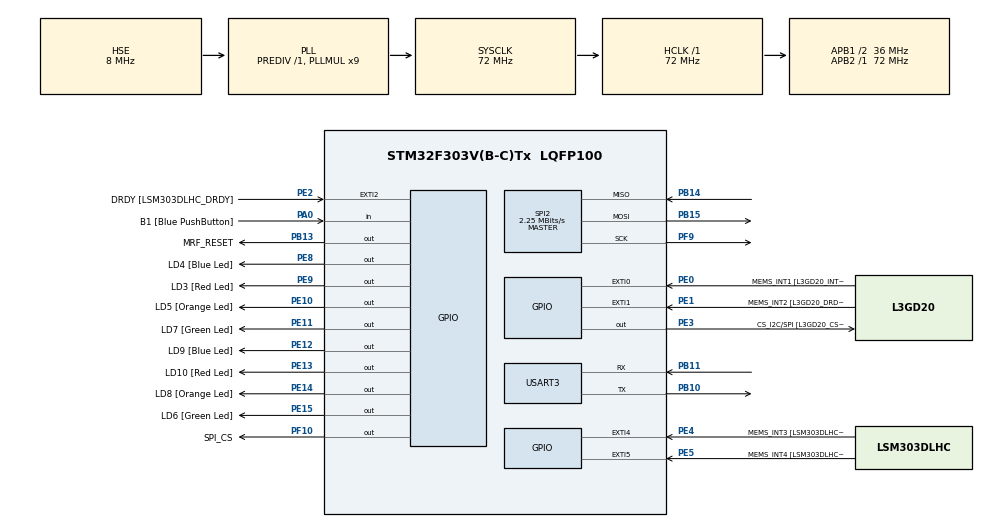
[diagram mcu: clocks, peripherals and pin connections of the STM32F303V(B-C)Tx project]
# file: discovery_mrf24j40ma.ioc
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Mcu.Family=STM32F3
Mcu.Name=STM32F303V(B-C)Tx
Mcu.Package=LQFP100
NVIC.PriorityGroup=NVIC_PRIORITYGROUP_0
NVIC.USART3_IRQn=true\:0\:0\:false\:false\:true
PA0.GPIO_Label=B1 [Blue PushButton]
PA0.GPIO_Mode=GPIO_MODE_INPUT
PA0.GPIO_PuPd=GPIO_NOPULL
PA0.Signal=GPIO_Input
PA11.GPIO_Label=DM
PA11.Signal=USB_DM
PA12.GPIO_Label=DP
PA12.Signal=USB_DP
PA13.GPIO_Label=SWDIO
PA13.Signal=SYS_JTMS-SWDIO
PA14.GPIO_Label=SWCLK
PA14.Signal=SYS_JTCK-SWCLK
PA5.GPIO_Label=SPI1_SCK [L3GD20_SCL/SPC]
PA5.GPIO_Mode=GPIO_MODE_AF_PP
PA5.GPIO_PuPd=GPIO_NOPULL
PA5.GPIO_Speed=GPIO_SPEED_FREQ_LOW
PA5.Signal=SPI1_SCK
PA6.GPIO_Label=SPI1_MISO [L3GD20_SA0/SDO]
PA6.GPIO_Mode=GPIO_MODE_AF_PP
PA6.GPIO_PuPd=GPIO_NOPULL
PA6.GPIO_Speed=GPIO_SPEED_FREQ_LOW
PA6.Signal=SPI1_MISO
PA7.GPIO_Label=SPI1_MISO [L3GD20_SDA/SDI/SDO]
PA7.GPIO_Mode=GPIO_MODE_AF_PP
PA7.GPIO_PuPd=GPIO_NOPULL
PA7.GPIO_Speed=GPIO_SPEED_FREQ_LOW
PA7.Signal=SPI1_MOSI
PB10.GPIO_PuPd=GPIO_PULLUP
PB10.Mode=Asynchronous
PB10.Signal=USART3_TX
PB11.GPIO_PuPd=GPIO_PULLUP
PB11.Mode=Asynchronous
PB11.Signal=USART3_RX
PB13.GPIO_Label=MRF_RESET
PB13.GPIO_Speed=GPIO_SPEED_FREQ_HIGH
PB13.Signal=GPIO_Output
PB14.GPIO_PuPd=GPIO_PULLUP
PB14.Mode=Full_Duplex_Master
PB14.Signal=SPI2_MISO
PB15.GPIO_PuPd=GPIO_PULLUP
PB15.Mode=Full_Duplex_Master
PB15.Signal=SPI2_MOSI
PB3.GPIO_Label=SWO
PB3.Signal=SYS_JTDO-TRACESWO
PB6.GPIO_FM6=__NULL
PB6.GPIO_Label=I2C1_SCL [LSM303DLHC_SCL]
PB6.GPIO_Mode=GPIO_MODE_AF_OD
PB6.GPIO_PuPd=GPIO_NOPULL
PB6.GPIO_Speed=GPIO_SPEED_FREQ_LOW
PB6.Signal=I2C1_SCL
PB7.GPIO_FM7=__NULL
PB7.GPIO_Label=I2C1_SDA [LSM303DLHC_SDA]
PB7.GPIO_Mode=GPIO_MODE_AF_OD
PB7.GPIO_PuPd=GPIO_NOPULL
PB7.GPIO_Speed=GPIO_SPEED_FREQ_LOW
PB7.Signal=I2C1_SDA
PC14-OSC32_IN.GPIO_Label=OSC32_IN
PC14-OSC32_IN.Signal=RCC_OSC32_IN
PC15-OSC32_OUT.GPIO_Label=OSC32_OUT
PC15-OSC32_OUT.Signal=RCC_OSC32_OUT
PE0.GPIO_Label=MEMS_INT1 [L3GD20_INT1]
PE0.GPIO_ModeDefaultEXTI=GPIO_MODE_EVT_RISING
PE0.GPIO_PuPd=GPIO_NOPULL
PE0.Signal=GPXTI0
PE1.GPIO_Label=MEMS_INT2 [L3GD20_DRDY/INT2]
PE1.GPIO_ModeDefaultEXTI=GPIO_MODE_EVT_RISING
PE1.GPIO_PuPd=GPIO_NOPULL
PE1.Signal=GPXTI1
PE10.GPIO_Label=LD5 [Orange Led]
PE10.GPIO_ModeDefaultOutputPP=GPIO_MODE_OUTPUT_PP
PE10.GPIO_PuPd=GPIO_NOPULL
PE10.GPIO_Speed=GPIO_SPEED_FREQ_LOW
PE10.Signal=GPIO_Output
PE11.GPIO_Label=LD7 [Green Led]
PE11.GPIO_ModeDefaultOutputPP=GPIO_MODE_OUTPUT_PP
PE11.GPIO_PuPd=GPIO_NOPULL
PE11.GPIO_Speed=GPIO_SPEED_FREQ_LOW
PE11.Signal=GPIO_Output
PE12.GPIO_Label=LD9 [Blue Led]
PE12.GPIO_ModeDefaultOutputPP=GPIO_MODE_OUTPUT_PP
PE12.GPIO_PuPd=GPIO_NOPULL
PE12.GPIO_Speed=GPIO_SPEED_FREQ_LOW
PE12.Signal=GPIO_Output
PE13.GPIO_Label=LD10 [Red Led]
PE13.GPIO_ModeDefaultOutputPP=GPIO_MODE_OUTPUT_PP
PE13.GPIO_PuPd=GPIO_NOPULL
PE13.GPIO_Speed=GPIO_SPEED_FREQ_LOW
PE13.Signal=GPIO_Output
PE14.GPIO_Label=LD8 [Orange Led]
PE14.GPIO_ModeDefaultOutputPP=GPIO_MODE_OUTPUT_PP
PE14.GPIO_PuPd=GPIO_NOPULL
PE14.GPIO_Speed=GPIO_SPEED_FREQ_LOW
PE14.Signal=GPIO_Output
PE15.GPIO_Label=LD6 [Green Led]
PE15.GPIO_ModeDefaultOutputPP=GPIO_MODE_OUTPUT_PP
PE15.GPIO_PuPd=GPIO_NOPULL
PE15.GPIO_Speed=GPIO_SPEED_FREQ_LOW
PE15.Signal=GPIO_Output
PE2.GPIO_Label=DRDY [LSM303DLHC_DRDY]
PE2.GPIO_ModeDefaultEXTI=GPIO_MODE_EVT_RISING
PE2.GPIO_PuPd=GPIO_NOPULL
PE2.Signal=GPXTI2
PE3.GPIO_Label=CS_I2C/SPI [L3GD20_CS_I2C/SPI]
PE3.GPIO_ModeDefaultOutputPP=GPIO_MODE_OUTPUT_PP
PE3.GPIO_PuPd=GPIO_NOPULL
PE3.GPIO_Speed=GPIO_SPEED_FREQ_LOW
PE3.Signal=GPIO_Output
PE4.GPIO_Label=MEMS_INT3 [LSM303DLHC_INT1]
PE4.GPIO_ModeDefaultEXTI=GPIO_MODE_EVT_RISING
PE4.GPIO_PuPd=GPIO_NOPULL
PE4.Signal=GPXTI4
PE5.GPIO_Label=MEMS_INT4 [LSM303DLHC_INT2]
PE5.GPIO_ModeDefaultEXTI=GPIO_MODE_EVT_RISING
PE5.GPIO_PuPd=GPIO_NOPULL
PE5.Signal=GPXTI5
PE8.GPIO_Label=LD4 [Blue Led]
PE8.GPIO_ModeDefaultOutputPP=GPIO_MODE_OUTPUT_PP
PE8.GPIO_PuPd=GPIO_NOPULL
PE8.GPIO_Speed=GPIO_SPEED_FREQ_LOW
PE8.Signal=GPIO_Output
PE9.GPIO_Label=LD3 [Red Led]
PE9.GPIO_ModeDefaultOutputPP=GPIO_MODE_OUTPUT_PP
PE9.GPIO_PuPd=GPIO_NOPULL
PE9.GPIO_Speed=GPIO_SPEED_FREQ_LOW
PE9.Signal=GPIO_Output
PF0-OSC_IN.GPIO_Label=OSC_IN
PF0-OSC_IN.Mode=HSE-External-Oscillator
PF0-OSC_IN.Signal=RCC_OSC_IN
PF1-OSC_OUT.GPIO_Label=OSC_OUT
PF1-OSC_OUT.Mode=HSE-External-Oscillator
PF1-OSC_OUT.Signal=RCC_OSC_OUT
PF10.GPIO_Label=SPI_CS
PF10.GPIO_PuPd=GPIO_PULLDOWN
PF10.GPIO_Speed=GPIO_SPEED_FREQ_HIGH
PF10.Signal=GPIO_Output
PF9.GPIO_PuPd=GPIO_PULLUP
PF9.Mode=Full_Duplex_Master
PF9.Signal=SPI2_SCK
ProjectManager.HeapSize=0x200
ProjectManager.StackSize=0x200
ProjectManager.TargetToolchain=SW4STM32
RCC.AHBFreq_Value=72000000
RCC.APB1CLKDivider=RCC_HCLK_DIV2
RCC.APB1Freq_Value=36000000
RCC.APB1TimFreq_Value=72000000
RCC.APB2Freq_Value=72000000
RCC.APB2TimFreq_Value=72000000
RCC.CortexFreq_Value=72000000
RCC.HCLKFreq_Value=72000000
RCC.HSE_VALUE=8000000
RCC.HSI_VALUE=8000000
RCC.LSE_VALUE=32768
RCC.PLLMUL=RCC_PLL_MUL9
RCC.PLLSourceVirtual=RCC_PLLSOURCE_HSE
RCC.SYSCLKFreq_VALUE=72000000
RCC.SYSCLKSourceVirtual=RCC_SYSCLKSOURCE_PLLCLK
RCC.USBFreq_Value=72000000
SPI2.BaudRatePrescaler=SPI_BAUDRATEPRESCALER_16
SPI2.CLKPolarity=SPI_POLARITY_LOW
SPI2.CalculateBaudRate=2.25 MBits/s
SPI2.DataSize=SPI_DATASIZE_8BIT
SPI2.Direction=SPI_DIRECTION_2LINES
SPI2.FirstBit=SPI_FIRSTBIT_MSB
SPI2.Mode=SPI_MODE_MASTER
SPI2.NSSPMode=SPI_NSS_PULSE_ENABLE
SPI2.VirtualType=VM_MASTER
USART3.VirtualMode-Asynchronous=VM_ASYNC
board=STM32F3DISCOVERY

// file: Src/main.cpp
/**
  ******************************************************************************
  * File Name          : main.c
  * Description        : Main program body
  ******************************************************************************
  ** This notice applies to any and all portions of this file
  * that are not between comment pairs USER CODE BEGIN and
  * USER CODE END. Other portions of this file, whether
  * inserted by the user or by software development tools
  * are owned by their respective copyright owners.
  *
  * COPYRIGHT(c) 2017 STMicroelectronics
  *
  * Redistribution and use in source and binary forms, with or without modification,
  * are permitted provided that the following conditions are met:
  *   1. Redistributions of source code must retain the above copyright notice,
  *      this list of conditions and the following disclaimer.
  *   2. Redistributions in binary form must reproduce the above copyright notice,
  *      this list of conditions and the following disclaimer in the documentation
  *      and/or other materials provided with the distribution.
  *   3. Neither the name of STMicroelectronics nor the names of its contributors
  *      may be used to endorse or promote products derived from this software
  *      without specific prior written permission.
  *
  * THIS SOFTWARE IS PROVIDED BY THE COPYRIGHT HOLDERS AND CONTRIBUTORS "AS IS"
  * AND ANY EXPRESS OR IMPLIED WARRANTIES, INCLUDING, BUT NOT LIMITED TO, THE
  * IMPLIED WARRANTIES OF MERCHANTABILITY AND FITNESS FOR A PARTICULAR PURPOSE ARE
  * DISCLAIMED. IN NO EVENT SHALL THE COPYRIGHT HOLDER OR CONTRIBUTORS BE LIABLE
  * FOR ANY DIRECT, INDIRECT, INCIDENTAL, SPECIAL, EXEMPLARY, OR CONSEQUENTIAL
  * DAMAGES (INCLUDING, BUT NOT LIMITED TO, PROCUREMENT OF SUBSTITUTE GOODS OR
  * SERVICES; LOSS OF USE, DATA, OR PROFITS; OR BUSINESS INTERRUPTION) HOWEVER
  * CAUSED AND ON ANY THEORY OF LIABILITY, WHETHER IN CONTRACT, STRICT LIABILITY,
  * OR TORT (INCLUDING NEGLIGENCE OR OTHERWISE) ARISING IN ANY WAY OUT OF THE USE
  * OF THIS SOFTWARE, EVEN IF ADVISED OF THE POSSIBILITY OF SUCH DAMAGE.
  *
  ******************************************************************************
  */
#include "main.h"
#include "stm32f3xx_hal.h"
#include "Mrf24j.h"
#include <stdlib.h>

SPI_HandleTypeDef hspi2;

UART_HandleTypeDef huart3;

/* USER CODE BEGIN PV */
/* Private variables ---------------------------------------------------------*/

/* USER CODE END PV */

void SystemClock_Config(void);
static void MX_GPIO_Init(void);
static void MX_SPI2_Init(void);
static void MX_USART3_UART_Init(void);

/* USER CODE BEGIN PFP */
/* Private function prototypes -----------------------------------------------*/

/* USER CODE END PFP */

void rx_handl();
void tx_handl();
uint8_t recvBuf[1];
constexpr uint16_t RECV_SIZE = 1;
Mrf24j *mrf24j;

int main(void)
{

  /* MCU Configuration----------------------------------------------------------*/

  /* Reset of all peripherals, Initializes the Flash interface and the Systick. */
  HAL_Init();

  /* Configure the system clock */
  SystemClock_Config();

  /* Initialize all configured peripherals */
  MX_GPIO_Init();
  MX_SPI2_Init();
  MX_USART3_UART_Init();

  gpio_pin pin_reset, pin_chip_select, pin_interrupt;

  pin_chip_select.port = SPI_CS_GPIO_Port;
  pin_chip_select.pin = SPI_CS_Pin;

  pin_reset.port = MRF_RESET_GPIO_Port;
  pin_reset.pin = MRF_RESET_Pin;

  mrf24j = new Mrf24j(&hspi2, &pin_reset, &pin_chip_select, &pin_interrupt);
  //Mrf24j mrf24j(&hspi2, &pin_reset, &pin_chip_select, &pin_interrupt);

  HAL_Delay(20);

  mrf24j->reset();
  mrf24j->init();

  mrf24j->set_pan(0x0023);
  // This is _our_ address
  mrf24j->address16_write(0x6001);

  //(word dest16, char * data, byte len) {
  /* Infinite loop */
  /* USER CODE BEGIN WHILE */

  HAL_UART_Receive_IT(&huart3, recvBuf, RECV_SIZE);

  uint8_t data[] = "WELCOME\n\r";
  uint8_t size = sizeof(data) / sizeof(data[0]);
  HAL_UART_Transmit_IT(&huart3, data, size);

  //char one[] = "ABCDEFGIH";
  char one[] = {
      0xf4, 0x3e, 0x01, 0xff, 0xff,
      0x2e, 0x21, 0x00, 0x0b, 0x00, 0x0b, 0x00, 0x10, 0x5e, 0xc0, 0x00, 0x5d, 0x00, 0x5d,
      0x80, 0x39, 0x47, 0x02, 0x33, 0xff, 0xff};
  int da_size = sizeof(one) / sizeof(one[0]);
  mrf24j->send16(0xffff, one, da_size);

  while (1)
  {

    //mrf24j->interrupt_handler();
    //HAL_Delay(100);
    //mrf24j->check_flags(rx_handl, tx_handl);
    mrf24j->send16(0xffff, one, da_size);

    //HAL_Delay(10);
    //mrf24j->read_long(MRF_RFCON0);
    //mrf24j->interrupt_handler();
    //mrf24j->check_flags(rx_handl, tx_handl);

    HAL_Delay(10000);
    /* USER CODE END WHILE */

  }

}
void rx_handl(){

}
void tx_handl(){

}

void HAL_UART_RxCpltCallback(UART_HandleTypeDef *huart){
  // Reactivate uart recv.

  switch(recvBuf[0])
  {
  case 13:
  {
    uint8_t data[] = "\n\r";
    HAL_UART_Transmit(huart, data, 2, 10);
  }
  break;
  case '1':
  {
    uint8_t ret[1];
    ret[0] = mrf24j->get_channel();
    ret[0] += 48 ; // Get ascii representation of decimal numbers.

    uint8_t mess1[] = "CHANNEL: 1";
    uint8_t size1 = sizeof(mess1) / sizeof(mess1[0]);
    HAL_UART_Transmit(huart, mess1, size1,10);
    HAL_UART_Transmit(huart, ret, 1,10);
    uint8_t mess2[] = "\n\r";
    HAL_UART_Transmit(huart, mess2, 2,10);
  }
    break;
  case '2':
  {
    uint16_t ret[2];
    ret[0] = mrf24j->get_pan();
    ret[1] = mrf24j->read_long(MRF_RFCON3);
    ret[0] += 48 ; // Get ascii representation of decimal numbers.

    uint8_t mess1[] = "CHANNEL: 1";
    uint8_t size1 = sizeof(mess1) / sizeof(mess1[0]);
    HAL_UART_Transmit(huart, mess1, size1,10);
    //HAL_UART_Transmit(huart, ret, 1,10);
    uint8_t mess2[] = "\n\r";
    HAL_UART_Transmit(huart, mess2, 2,10);
  }
  break;
  case '3':
  {
    mrf24j->set_pan(0x0077);
  }
  break;
  default:
    HAL_UART_Transmit(huart, recvBuf, RECV_SIZE,10);

  }

  HAL_UART_Receive_IT(huart, recvBuf, RECV_SIZE);
}

/** System Clock Configuration
*/
void SystemClock_Config(void)
{

  RCC_OscInitTypeDef RCC_OscInitStruct;
  RCC_ClkInitTypeDef RCC_ClkInitStruct;
  RCC_PeriphCLKInitTypeDef PeriphClkInit;

    /**Initializes the CPU, AHB and APB busses clocks
    */
  RCC_OscInitStruct.OscillatorType = RCC_OSCILLATORTYPE_HSE;
  RCC_OscInitStruct.HSEState = RCC_HSE_ON;
  RCC_OscInitStruct.HSEPredivValue = RCC_HSE_PREDIV_DIV1;
  RCC_OscInitStruct.HSIState = RCC_HSI_ON;
  RCC_OscInitStruct.PLL.PLLState = RCC_PLL_ON;
  RCC_OscInitStruct.PLL.PLLSource = RCC_PLLSOURCE_HSE;
  RCC_OscInitStruct.PLL.PLLMUL = RCC_PLL_MUL9;
  if (HAL_RCC_OscConfig(&RCC_OscInitStruct) != HAL_OK)
  {
    _Error_Handler(__FILE__, __LINE__);
  }

    /**Initializes the CPU, AHB and APB busses clocks
    */
  RCC_ClkInitStruct.ClockType = RCC_CLOCKTYPE_HCLK|RCC_CLOCKTYPE_SYSCLK
                              |RCC_CLOCKTYPE_PCLK1|RCC_CLOCKTYPE_PCLK2;
  RCC_ClkInitStruct.SYSCLKSource = RCC_SYSCLKSOURCE_PLLCLK;
  RCC_ClkInitStruct.AHBCLKDivider = RCC_SYSCLK_DIV1;
  RCC_ClkInitStruct.APB1CLKDivider = RCC_HCLK_DIV2;
  RCC_ClkInitStruct.APB2CLKDivider = RCC_HCLK_DIV1;

  if (HAL_RCC_ClockConfig(&RCC_ClkInitStruct, FLASH_LATENCY_2) != HAL_OK)
  {
    _Error_Handler(__FILE__, __LINE__);
  }

  PeriphClkInit.PeriphClockSelection = RCC_PERIPHCLK_USART3;
  PeriphClkInit.Usart3ClockSelection = RCC_USART3CLKSOURCE_PCLK1;
  if (HAL_RCCEx_PeriphCLKConfig(&PeriphClkInit) != HAL_OK)
  {
    _Error_Handler(__FILE__, __LINE__);
  }

    /**Configure the Systick interrupt time
    */
  HAL_SYSTICK_Config(HAL_RCC_GetHCLKFreq()/1000);

    /**Configure the Systick
    */
  HAL_SYSTICK_CLKSourceConfig(SYSTICK_CLKSOURCE_HCLK);

  /* SysTick_IRQn interrupt configuration */
  HAL_NVIC_SetPriority(SysTick_IRQn, 0, 0);
}

/* SPI2 init function */
static void MX_SPI2_Init(void)
{

  hspi2.Instance = SPI2;
  hspi2.Init.Mode = SPI_MODE_MASTER;
  hspi2.Init.Direction = SPI_DIRECTION_2LINES;
  hspi2.Init.DataSize = SPI_DATASIZE_8BIT;
  hspi2.Init.CLKPolarity = SPI_POLARITY_LOW;
  hspi2.Init.CLKPhase = SPI_PHASE_1EDGE;
  hspi2.Init.NSS = SPI_NSS_SOFT;
  hspi2.Init.BaudRatePrescaler = SPI_BAUDRATEPRESCALER_16;
  hspi2.Init.FirstBit = SPI_FIRSTBIT_MSB;
  hspi2.Init.TIMode = SPI_TIMODE_DISABLE;
  hspi2.Init.CRCCalculation = SPI_CRCCALCULATION_DISABLE;
  hspi2.Init.CRCPolynomial = 7;
  hspi2.Init.CRCLength = SPI_CRC_LENGTH_DATASIZE;
  hspi2.Init.NSSPMode = SPI_NSS_PULSE_ENABLE;
  if (HAL_SPI_Init(&hspi2) != HAL_OK)
  {
    _Error_Handler(__FILE__, __LINE__);
  }

}

/* USART3 init function */
static void MX_USART3_UART_Init(void)
{

  huart3.Instance = USART3;
  huart3.Init.BaudRate = 38400;
  huart3.Init.WordLength = UART_WORDLENGTH_8B;
  huart3.Init.StopBits = UART_STOPBITS_1;
  huart3.Init.Parity = UART_PARITY_NONE;
  huart3.Init.Mode = UART_MODE_TX_RX;
  huart3.Init.HwFlowCtl = UART_HWCONTROL_NONE;
  huart3.Init.OverSampling = UART_OVERSAMPLING_16;
  huart3.Init.OneBitSampling = UART_ONE_BIT_SAMPLE_DISABLE;
  huart3.AdvancedInit.AdvFeatureInit = UART_ADVFEATURE_NO_INIT;
  if (HAL_UART_Init(&huart3) != HAL_OK)
  {
    _Error_Handler(__FILE__, __LINE__);
  }

}

/** Configure pins as
        * Analog
        * Input
        * Output
        * EVENT_OUT
        * EXTI
     PA5   ------> SPI1_SCK
     PA6   ------> SPI1_MISO
     PA7   ------> SPI1_MOSI
     PA11   ------> USB_DM
     PA12   ------> USB_DP
     PB6   ------> I2C1_SCL
     PB7   ------> I2C1_SDA
*/
static void MX_GPIO_Init(void)
{

  GPIO_InitTypeDef GPIO_InitStruct;

  /* GPIO Ports Clock Enable */
  __HAL_RCC_GPIOE_CLK_ENABLE();
  __HAL_RCC_GPIOC_CLK_ENABLE();
  __HAL_RCC_GPIOF_CLK_ENABLE();
  __HAL_RCC_GPIOA_CLK_ENABLE();
  __HAL_RCC_GPIOB_CLK_ENABLE();

  /*Configure GPIO pin Output Level */
  HAL_GPIO_WritePin(GPIOE, CS_I2C_SPI_Pin|LD4_Pin|LD3_Pin|LD5_Pin
                          |LD7_Pin|LD9_Pin|LD10_Pin|LD8_Pin
                          |LD6_Pin, GPIO_PIN_RESET);

  /*Configure GPIO pin Output Level */
  HAL_GPIO_WritePin(SPI_CS_GPIO_Port, SPI_CS_Pin, GPIO_PIN_RESET);

  /*Configure GPIO pin Output Level */
  HAL_GPIO_WritePin(MRF_RESET_GPIO_Port, MRF_RESET_Pin, GPIO_PIN_RESET);

  /*Configure GPIO pins : DRDY_Pin MEMS_INT3_Pin MEMS_INT4_Pin MEMS_INT1_Pin
                           MEMS_INT2_Pin */
  GPIO_InitStruct.Pin = DRDY_Pin|MEMS_INT3_Pin|MEMS_INT4_Pin|MEMS_INT1_Pin
                          |MEMS_INT2_Pin;
  GPIO_InitStruct.Mode = GPIO_MODE_EVT_RISING;
  GPIO_InitStruct.Pull = GPIO_NOPULL;
  HAL_GPIO_Init(GPIOE, &GPIO_InitStruct);

  /*Configure GPIO pins : CS_I2C_SPI_Pin LD4_Pin LD3_Pin LD5_Pin
                           LD7_Pin LD9_Pin LD10_Pin LD8_Pin
                           LD6_Pin */
  GPIO_InitStruct.Pin = CS_I2C_SPI_Pin|LD4_Pin|LD3_Pin|LD5_Pin
                          |LD7_Pin|LD9_Pin|LD10_Pin|LD8_Pin
                          |LD6_Pin;
  GPIO_InitStruct.Mode = GPIO_MODE_OUTPUT_PP;
  GPIO_InitStruct.Pull = GPIO_NOPULL;
  GPIO_InitStruct.Speed = GPIO_SPEED_FREQ_LOW;
  HAL_GPIO_Init(GPIOE, &GPIO_InitStruct);

  /*Configure GPIO pin : SPI_CS_Pin */
  GPIO_InitStruct.Pin = SPI_CS_Pin;
  GPIO_InitStruct.Mode = GPIO_MODE_OUTPUT_PP;
  GPIO_InitStruct.Pull = GPIO_PULLDOWN;
  GPIO_InitStruct.Speed = GPIO_SPEED_FREQ_HIGH;
  HAL_GPIO_Init(SPI_CS_GPIO_Port, &GPIO_InitStruct);

  /*Configure GPIO pin : B1_Pin */
  GPIO_InitStruct.Pin = B1_Pin;
  GPIO_InitStruct.Mode = GPIO_MODE_INPUT;
  GPIO_InitStruct.Pull = GPIO_NOPULL;
  HAL_GPIO_Init(B1_GPIO_Port, &GPIO_InitStruct);

  /*Configure GPIO pins : SPI1_SCK_Pin SPI1_MISO_Pin SPI1_MISOA7_Pin */
  GPIO_InitStruct.Pin = SPI1_SCK_Pin|SPI1_MISO_Pin|SPI1_MISOA7_Pin;
  GPIO_InitStruct.Mode = GPIO_MODE_AF_PP;
  GPIO_InitStruct.Pull = GPIO_NOPULL;
  GPIO_InitStruct.Speed = GPIO_SPEED_FREQ_LOW;
  GPIO_InitStruct.Alternate = GPIO_AF5_SPI1;
  HAL_GPIO_Init(GPIOA, &GPIO_InitStruct);

  /*Configure GPIO pin : MRF_RESET_Pin */
  GPIO_InitStruct.Pin = MRF_RESET_Pin;
  GPIO_InitStruct.Mode = GPIO_MODE_OUTPUT_PP;
  GPIO_InitStruct.Pull = GPIO_NOPULL;
  GPIO_InitStruct.Speed = GPIO_SPEED_FREQ_HIGH;
  HAL_GPIO_Init(MRF_RESET_GPIO_Port, &GPIO_InitStruct);

  /*Configure GPIO pins : DM_Pin DP_Pin */
  GPIO_InitStruct.Pin = DM_Pin|DP_Pin;
  GPIO_InitStruct.Mode = GPIO_MODE_AF_PP;
  GPIO_InitStruct.Pull = GPIO_NOPULL;
  GPIO_InitStruct.Speed = GPIO_SPEED_FREQ_HIGH;
  GPIO_InitStruct.Alternate = GPIO_AF14_USB;
  HAL_GPIO_Init(GPIOA, &GPIO_InitStruct);

  /*Configure GPIO pins : I2C1_SCL_Pin I2C1_SDA_Pin */
  GPIO_InitStruct.Pin = I2C1_SCL_Pin|I2C1_SDA_Pin;
  GPIO_InitStruct.Mode = GPIO_MODE_AF_OD;
  GPIO_InitStruct.Pull = GPIO_PULLUP;
  GPIO_InitStruct.Speed = GPIO_SPEED_FREQ_LOW;
  GPIO_InitStruct.Alternate = GPIO_AF4_I2C1;
  HAL_GPIO_Init(GPIOB, &GPIO_InitStruct);

}

void _Error_Handler(char * file, int line)
{
  while(1)
  {
  }
}

/************************ (C) COPYRIGHT STMicroelectronics *****END OF FILE****/
